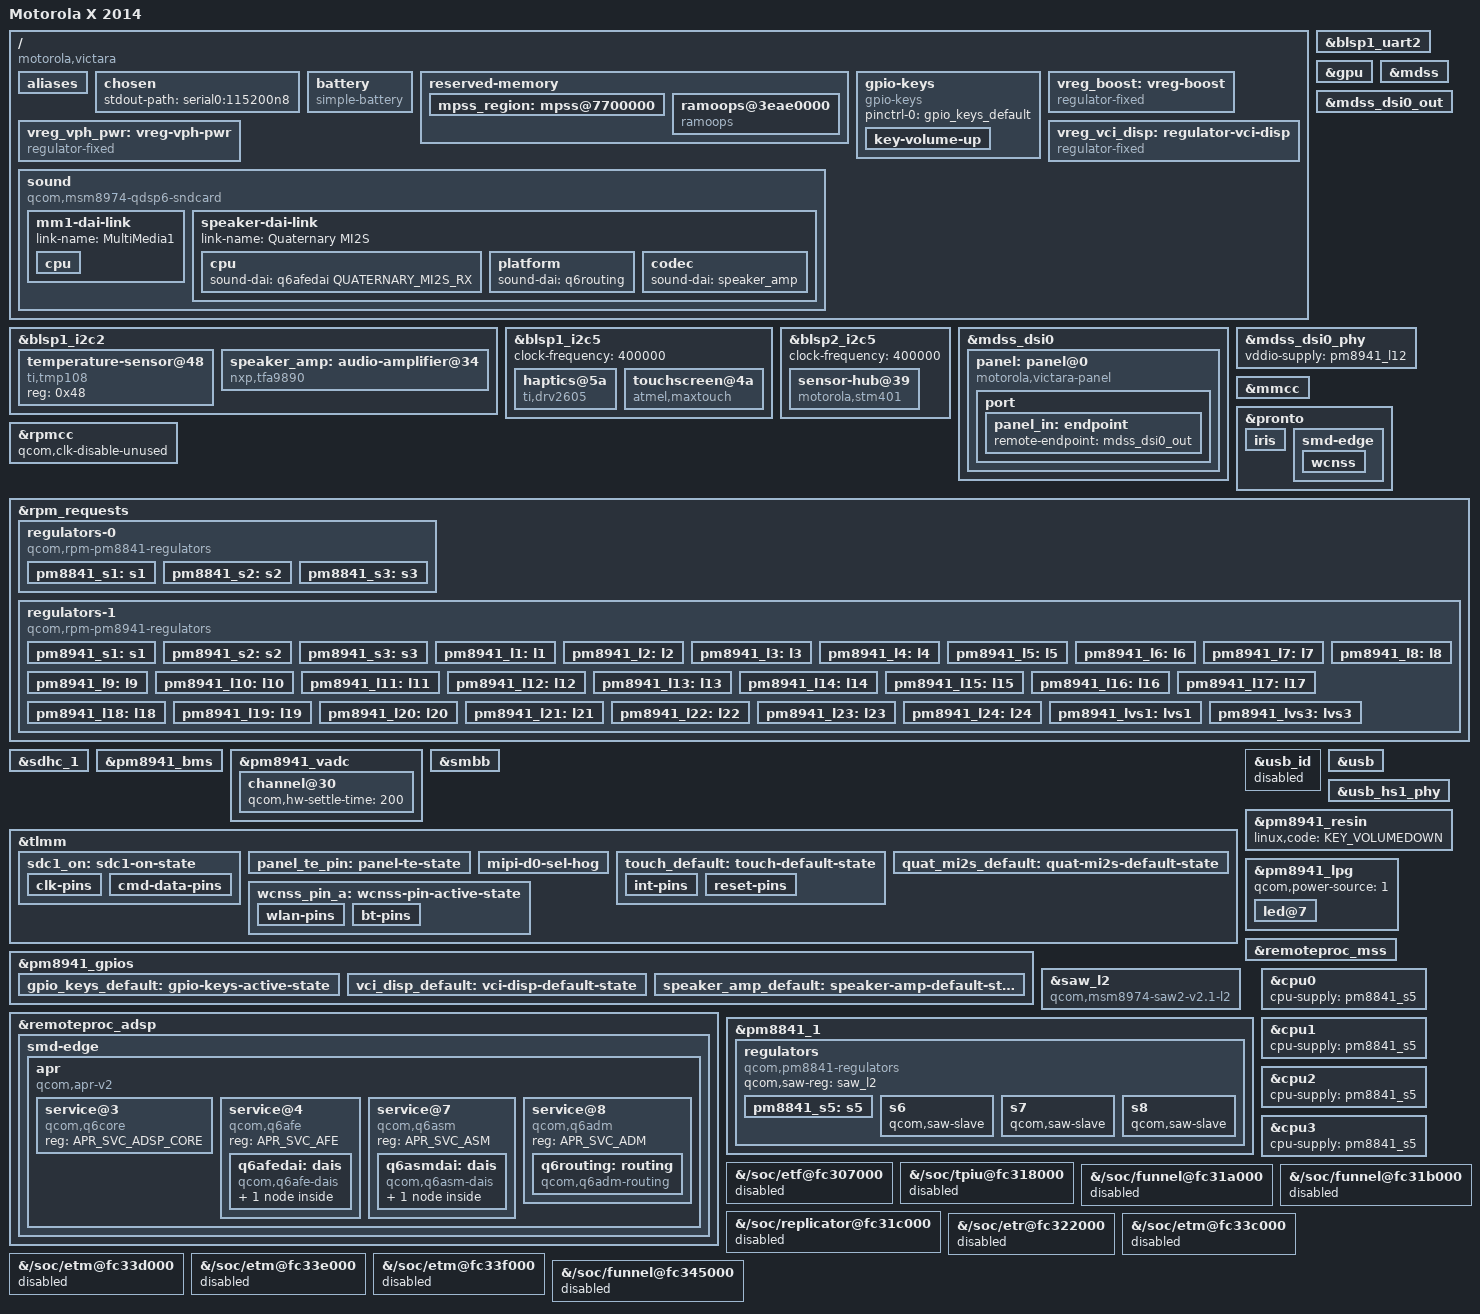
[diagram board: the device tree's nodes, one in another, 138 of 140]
// SPDX-License-Identifier: GPL-2.0
#include "qcom-msm8974pro.dtsi"
#include "pm8841.dtsi"
#include "pm8941.dtsi"
#include <dt-bindings/input/input.h>
#include <dt-bindings/input/ti-drv260x.h>
#include <dt-bindings/leds/common.h>
#include <dt-bindings/pinctrl/qcom,pmic-gpio.h>
#include <dt-bindings/soc/qcom,apr.h>
#include <dt-bindings/sound/qcom,q6afe.h>
#include <dt-bindings/sound/qcom,q6asm.h>

/delete-node/ &mpss_region;

/ {
       model = "Motorola X 2014";
       compatible = "motorola,victara", "qcom,msm8974pro", "qcom,msm8974";
       chassis-type = "handset";

       aliases {
               mmc0 = &sdhc_1;
               serial0 = &blsp1_uart2;
       };

       chosen {
               stdout-path = "serial0:115200n8";
       };

        battery: battery {
                compatible = "simple-battery";
                device-chemistry = "lithium-ion";
                charge-full-design-microamp-hours = <2281000>;
                voltage-min-design-microvolt = <3000000>;
                voltage-max-design-microvolt = <4200000>;
                factory-internal-resistance-micro-ohms = <188000>;

                ocv-capacity-celsius = <(-10) 0 23 60>;
                ocv-capacity-table-0 = <4300000 100>, <4266000 95>, <4209000 90>, <4156000 85>, <4106000 80>, <4058000 75>,
                                       <4002000 70>, <3954000 65>, <3910000 60>, <3873000 55>, <3843000 50>, <3820000 45>,
                                       <3802000 40>, <3791000 35>, <3782000 30>, <3767000 25>, <3742000 20>, <3714000 15>,
                                       <3696000 10>, <3693000 9>, <3689000 8>, <3683000 7>, <3669000 6>, <3640000 5>,
                                       <3594000 4>, <3529000 3>, <3438000 2>, <3293000 1>, <3000000 0>;
                ocv-capacity-table-1 = <4300000 100>, <4266000 95>, <4212000 90>, <4159000 85>, <4109000 80>, <4064000 75>,
                                       <4011000 70>, <3967000 65>, <3921000 60>, <3878000 55>, <3847000 50>, <3825000 45>,
                                       <3807000 40>, <3793000 35>, <3783000 30>, <3772000 25>, <3746000 20>, <3711000 15>,
                                       <3694000 10>, <3692000 9>, <3689000 8>, <3683000 7>, <3668000 6>, <3639000 5>,
                                       <3591000 4>, <3527000 3>, <3436000 2>, <3282000 1>, <3000000 0>;
                ocv-capacity-table-2 = <4300000 100>, <4262000 95>, <4207000 90>, <4155000 85>, <4105000 80>, <4059000 75>,
                                       <4011000 70>, <3970000 65>, <3933000 60>, <3877000 55>, <3847000 50>, <3825000 45>,
                                       <3807000 40>, <3793000 35>, <3780000 30>, <3763000 25>, <3736000 20>, <3695000 15>,
                                       <3685000 10>, <3683000 9>, <3681000 8>, <3675000 7>, <3656000 6>, <3624000 5>,
                                       <3577000 4>, <3512000 3>, <3422000 2>, <3280000 1>, <3000000 0>;
                ocv-capacity-table-3 = <4300000 100>, <4249000 95>, <4195000 90>, <4144000 85>, <4095000 80>, <4048000 75>,
                                       <4004000 70>, <3965000 65>, <3921000 60>, <3874000 55>, <3846000 50>, <3823000 45>,
                                       <3804000 40>, <3788000 35>, <3759000 30>, <3735000 25>, <3710000 20>, <3678000 15>,
                                       <3664000 10>, <3663000 9>, <3660000 8>, <3650000 7>, <3626000 6>, <3586000 5>,
                                       <3534000 4>, <3467000 3>, <3374000 2>, <3231000 1>, <3000000 0>;
        };

        reserved-memory {
                mpss_region: mpss@7700000 {
                        reg = <0x07700000 0x5a00000>;
                        no-map;
                };

                ramoops@3eae0000 {
                        compatible = "ramoops";
                        reg = <0x3eae0000 0x20000>;
                        console-size = <0x20000>;
                        record-size = <0x0>;
                        pmsg-size = <0x0>;
                        mem-type = <1>;
                };
        };

        gpio-keys {
                compatible = "gpio-keys";

                pinctrl-names = "default";
                pinctrl-0 = <&gpio_keys_default>;

                key-volume-up {
                        label = "volume_up";
                        gpios = <&pm8941_gpios 5 GPIO_ACTIVE_LOW>;
                        linux,code = <KEY_VOLUMEUP>;
                        wakeup-source;
                        debounce-interval = <15>;
                };
        };

       vreg_boost: vreg-boost {
                compatible = "regulator-fixed";

                regulator-name = "vreg-boost";
                regulator-min-microvolt = <3150000>;
                regulator-max-microvolt = <3150000>;

                regulator-always-on;
                regulator-boot-on;

                gpio = <&pm8941_gpios 21 GPIO_ACTIVE_HIGH>;
                enable-active-high;

                pinctrl-names = "default";
                pinctrl-0 = <&boost_bypass_n_pin>;
        };

        vreg_vph_pwr: vreg-vph-pwr {
                compatible = "regulator-fixed";
                regulator-name = "vph-pwr";

                regulator-min-microvolt = <3600000>;
                regulator-max-microvolt = <3600000>;

                regulator-always-on;
        };

        vreg_vci_disp: regulator-vci-disp {
                compatible = "regulator-fixed";
                regulator-name = "vci_disp";

                regulator-min-microvolt = <3300000>;
                regulator-max-microvolt = <3300000>;

                gpio = <&pm8941_gpios 14 GPIO_ACTIVE_HIGH>;
                enable-active-high;
                startup-delay-us = <300>;

                vin-supply = <&pm8941_l23>;

                regulator-boot-on;

                pinctrl-0 = <&vci_disp_default>;
                pinctrl-names = "default";
        };

        sound {
                compatible = "qcom,msm8974-qdsp6-sndcard";
                model = "msm8974";

                pinctrl-0 = <&quat_mi2s_default>;
                pinctrl-names = "default";

                mm1-dai-link {
                        link-name = "MultiMedia1";

                        cpu {
                                sound-dai = <&q6asmdai MSM_FRONTEND_DAI_MULTIMEDIA1>;
                        };
                };

                speaker-dai-link {
                        link-name = "Quaternary MI2S";

                        cpu {
                                sound-dai = <&q6afedai QUATERNARY_MI2S_RX>;
                        };

                        platform {
                                sound-dai = <&q6routing>;
                        };

                        codec {
                                sound-dai = <&speaker_amp>;
                        };
                };
        };
};

&blsp1_i2c2 {
        status = "okay";

        temperature-sensor@48 {
                compatible = "ti,tmp108";
                reg = <0x48>;
                #thermal-sensor-cells = <0>;
        };

        speaker_amp: audio-amplifier@34 {
                compatible = "nxp,tfa9890";
                reg = <0x34>;

                vddd-supply = <&pm8941_s3>;

                pinctrl-0 = <&speaker_amp_default>;
                pinctrl-names = "default";

                sound-name-prefix = "Speaker";
                #sound-dai-cells = <0>;
        };
};

&blsp1_i2c5 {
        status = "okay";
        clock-frequency = <400000>;

        haptics@5a {
                compatible = "ti,drv2605";
                reg = <0x5a>;

                vbat-supply = <&pm8941_5v>;
                enable-gpios = <&tlmm 45 GPIO_ACTIVE_HIGH>;

                mode = <DRV260X_ERM_MODE>;
                library-sel = <DRV260X_ERM_LIB_A>;
                vib-rated-mv = <2503>;
                vib-overdrive-mv = <3008>;
        };

        touchscreen@4a {
                compatible = "atmel,maxtouch";
                reg = <0x4a>;

                interrupts-extended = <&tlmm 62 IRQ_TYPE_EDGE_FALLING>;
                reset-gpios = <&tlmm 57 GPIO_ACTIVE_LOW>;

                vdda-supply = <&pm8941_l23>;
                vdd-supply = <&pm8941_s3>;

                pinctrl-0 = <&touch_default>;
                pinctrl-names = "default";
        };
};

&blsp1_uart2 {
       status = "okay";
};

&blsp2_i2c5 {
        status = "okay";
        clock-frequency = <400000>;

        sensor-hub@39 {
                compatible = "motorola,stm401";
                reg = <0x39>;

                interrupts-extended = <&tlmm 14 IRQ_TYPE_EDGE_RISING>,
                                      <&tlmm 95 IRQ_TYPE_EDGE_RISING>;
                interrupt-names = "data", "wakeup";

                reset-gpios = <&tlmm 145 GPIO_ACTIVE_LOW>;
                boot-gpios = <&tlmm 33 GPIO_ACTIVE_HIGH>;
                wakeup-gpios = <&tlmm 0 GPIO_ACTIVE_HIGH>;
                wakeup-ack-gpios = <&tlmm 1 GPIO_ACTIVE_HIGH>;

                vio-supply = <&pm8941_lvs1>;
                vdd-supply = <&pm8941_l17>;

                motorola,lux-table = <6 70 86 1174 2800 8000>;
                motorola,brightness-table = <12 20 25 55 80 111 165>;
                motorola,prox-settings = <0x6e 0x50 0x64 0x04>;
        };
};

&gpu {
        status = "okay";
};

&mdss {
        status = "okay";
};

&mdss_dsi0 {
        status = "okay";

        vdda-supply = <&pm8941_l2>;
        vddio-supply = <&pm8941_l12>;

        panel: panel@0 {
                compatible = "motorola,victara-panel";
                reg = <0>;

                vci-supply = <&vreg_vci_disp>;
                vddio-supply = <&pm8941_l12>;

                reset-gpios = <&pm8941_gpios 12 GPIO_ACTIVE_LOW>;

                pinctrl-0 = <&panel_te_pin>;
                pinctrl-names = "default";

                port {
                        panel_in: endpoint {
                                remote-endpoint = <&mdss_dsi0_out>;
                        };
                };
        };
};

&mdss_dsi0_out {
        remote-endpoint = <&panel_in>;
        data-lanes = <0 1 2 3>;
};

&mdss_dsi0_phy {
        status = "okay";

        vddio-supply = <&pm8941_l12>;
};

&mmcc {
        power-domains = <&rpmpd MSM8974_VDDGFX>;
        required-opps = <&rpmpd_opp_svs_soc>;
};

&pronto {
        status = "okay";

        vddmx-supply = <&pm8841_s1>;
        vddpx-supply = <&pm8941_s3>;

        pinctrl-names = "default";
        pinctrl-0 = <&wcnss_pin_a>;

        iris {
                vddxo-supply = <&pm8941_l6>;
                vddrfa-supply = <&pm8941_l11>;
                vddpa-supply = <&pm8941_l21>;
                vdddig-supply = <&pm8941_s3>;
        };

        smd-edge {
                qcom,remote-pid = <4>;
                label = "pronto";

                wcnss {
                        status = "okay";
                };
        };
};

&rpmcc {
        qcom,clk-disable-unused;
};

&rpm_requests {
        regulators-0 {
                compatible = "qcom,rpm-pm8841-regulators";

                pm8841_s1: s1 {
                        regulator-min-microvolt = <675000>;
                        regulator-max-microvolt = <1050000>;
                };

                pm8841_s2: s2 {
                        regulator-min-microvolt = <500000>;
                        regulator-max-microvolt = <1050000>;
                };

                pm8841_s3: s3 {
                        regulator-min-microvolt = <1050000>;
                        regulator-max-microvolt = <1050000>;
                };
        };

        regulators-1 {
                compatible = "qcom,rpm-pm8941-regulators";

                vdd_l1_l3-supply = <&pm8941_s1>;
                vdd_l2_lvs1_2_3-supply = <&pm8941_s3>;
                vdd_l4_l11-supply = <&pm8941_s1>;
                vdd_l5_l7-supply = <&pm8941_s2>;
                vdd_l6_l12_l14_l15-supply = <&pm8941_s2>;
                vdd_l8_l16_l18_l19-supply = <&vreg_vph_pwr>;
                vdd_l9_l10_l17_l22-supply = <&vreg_boost>;
                vdd_l13_l20_l23_l24-supply = <&vreg_boost>;
                vdd_l21-supply = <&vreg_boost>;

                pm8941_s1: s1 {
                        regulator-min-microvolt = <1300000>;
                        regulator-max-microvolt = <1300000>;

                        regulator-always-on;
                        regulator-boot-on;
                };

                pm8941_s2: s2 {
                        regulator-min-microvolt = <2150000>;
                        regulator-max-microvolt = <2150000>;

                        regulator-boot-on;
                };

                pm8941_s3: s3 {
                        regulator-min-microvolt = <1800000>;
                        regulator-max-microvolt = <1800000>;
                        regulator-system-load = <154000>;

                        regulator-always-on;
                        regulator-boot-on;
                        regulator-allow-set-load;
                };

                pm8941_l1: l1 {
                        regulator-min-microvolt = <1225000>;
                        regulator-max-microvolt = <1225000>;

                        regulator-always-on;
                        regulator-boot-on;
                };

                pm8941_l2: l2 {
                        regulator-min-microvolt = <1200000>;
                        regulator-max-microvolt = <1200000>;
                };

                pm8941_l3: l3 {
                        regulator-min-microvolt = <1225000>;
                        regulator-max-microvolt = <1225000>;
                };

                pm8941_l4: l4 {
                        regulator-min-microvolt = <1225000>;
                        regulator-max-microvolt = <1225000>;
                };

                pm8941_l5: l5 {
                        regulator-min-microvolt = <1800000>;
                        regulator-max-microvolt = <1800000>;
                };

                pm8941_l6: l6 {
                        regulator-min-microvolt = <1800000>;
                        regulator-max-microvolt = <1800000>;

                        regulator-boot-on;
                };

                pm8941_l7: l7 {
                        regulator-min-microvolt = <1800000>;
                        regulator-max-microvolt = <1800000>;

                        regulator-boot-on;
                };

                pm8941_l8: l8 {
                        regulator-min-microvolt = <1800000>;
                        regulator-max-microvolt = <1800000>;
                };

                pm8941_l9: l9 {
                        regulator-min-microvolt = <1800000>;
                        regulator-max-microvolt = <2950000>;
                };

                pm8941_l10: l10 {
                        regulator-min-microvolt = <1800000>;
                        regulator-max-microvolt = <2950000>;
                };

                pm8941_l11: l11 {
                        regulator-min-microvolt = <1225000>;
                        regulator-max-microvolt = <1350000>;
                };

                pm8941_l12: l12 {
                        regulator-min-microvolt = <1800000>;
                        regulator-max-microvolt = <1800000>;

                        regulator-always-on;
                        regulator-boot-on;
                        regulator-allow-set-load;
                };

                pm8941_l13: l13 {
                        regulator-min-microvolt = <1800000>;
                        regulator-max-microvolt = <2950000>;

                        regulator-boot-on;
                };

                pm8941_l14: l14 {
                        regulator-min-microvolt = <1800000>;
                        regulator-max-microvolt = <1800000>;
                };

                pm8941_l15: l15 {
                        regulator-min-microvolt = <2050000>;
                        regulator-max-microvolt = <2050000>;
                };

                pm8941_l16: l16 {
                        regulator-min-microvolt = <2700000>;
                        regulator-max-microvolt = <2700000>;
                };

                pm8941_l17: l17 {
                        regulator-min-microvolt = <2850000>;
                        regulator-max-microvolt = <2850000>;
                };

                pm8941_l18: l18 {
                        regulator-min-microvolt = <2850000>;
                        regulator-max-microvolt = <2850000>;
                };

                pm8941_l19: l19 {
                        regulator-min-microvolt = <2900000>;
                        regulator-max-microvolt = <3350000>;
                };

                pm8941_l20: l20 {
                        regulator-min-microvolt = <2950000>;
                        regulator-max-microvolt = <2950000>;

                        regulator-system-load = <200000>;
                        regulator-allow-set-load;
                        regulator-boot-on;
                };

                pm8941_l21: l21 {
                        regulator-min-microvolt = <2900000>;
                        regulator-max-microvolt = <3350000>;

                        regulator-boot-on;
                        regulator-always-on;
                };

                pm8941_l22: l22 {
                        regulator-min-microvolt = <3000000>;
                        regulator-max-microvolt = <3000000>;
                        regulator-allow-set-load;
                };

                pm8941_l23: l23 {
                        regulator-min-microvolt = <3300000>;
                        regulator-max-microvolt = <3300000>;
                };

                pm8941_l24: l24 {
                        regulator-min-microvolt = <3075000>;
                        regulator-max-microvolt = <3075000>;

                        regulator-boot-on;
                };

                pm8941_lvs1: lvs1 {};

                pm8941_lvs3: lvs3 {};
        };
};

&sdhc_1 {
        status = "okay";
                        
        vmmc-supply = <&pm8941_l20>;
        vqmmc-supply = <&pm8941_s3>;

        pinctrl-names = "default", "sleep";
        pinctrl-0 = <&sdc1_on>;
        pinctrl-1 = <&sdc1_off>;
};

&pm8941_bms {
        io-channels = <&pm8941_vadc VADC_VBAT_SNS>,
                      <&pm8941_vadc VADC_REF_625MV>,
                      <&pm8941_vadc VADC_REF_1250MV>,
                      <&pm8941_vadc VADC_LR_MUX1_BAT_THERM>,
                      <&pm8941_vadc VADC_GND_REF>,
                      <&pm8941_vadc VADC_VDD_VADC>;
        io-channel-names = "vbat", "ref-625mv", "ref-1250mv", "therm", "gnd-ref", "vdd-vadc";

        qcom,fcc-temp-celsius = <(-10) 0 23 60>;
        qcom,fcc-microamp-hours = <1919000 2155000 2281000 2236000>;

        qcom,shutdown-soc-valid-limit-percent = <100>;

        qcom,rbatt-sf-celsius = <(-10) 0 23 60>;
        qcom,rbatt-sf-capacity = <100 95 90 85 80 75 70 65 60 55 50 45 40 35 30 25 20 15 10 9 8 7 6 5 4 3 2 1 0>;
        qcom,rbatt-sf = <607 314 100 62>, <615 323 104 64>, <624 332 107 67>, <636 342 111 71>,
                        <650 352 116 74>, <667 376 125 78>, <667 386 133 79>, <665 395 150 85>,
                        <656 378 163 89>, <655 359 119 73>, <670 360 113 73>, <698 375 121 76>,
                        <735 394 128 80>, <800 423 136 87>, <902 476 144 77>, <1015 553 138 74>,
                        <1108 620 135 76>, <1204 681 137 76>, <1200 685 148 80>, <1239 693 145 81>,
                        <1281 721 151 81>, <1327 745 156 83>, <1368 765 156 84>, <1402 780 160 81>,
                        <1451 805 165 81>, <1524 849 169 81>, <1624 907 178 87>, <1819 1018 201 201>,
                        <3032 1951 615 615>;

        monitored-battery = <&battery>;

        status = "okay";
};

&pm8941_vadc {
        channel@30 {
                qcom,hw-settle-time = <200>;
        };
};

&smbb {
        qcom,fast-charge-safe-current = <3000000>;
        qcom,fast-charge-current-limit = <2600000>;
        qcom,fast-charge-safe-voltage = <4400000>;
        qcom,fast-charge-high-threshold-voltage = <4200000>;
        qcom,auto-recharge-threshold-voltage = <4050000>;
        qcom,minimum-input-voltage = <4300000>;

        status = "okay";
};

&tlmm {         
        sdc1_on: sdc1-on-state {
                clk-pins { 
                        pins = "sdc1_clk";
                        drive-strength = <16>;
                        bias-disable;
                };

                cmd-data-pins {
                        pins = "sdc1_cmd", "sdc1_data";
                        drive-strength = <10>;
                        bias-pull-up;
                };
        };

        panel_te_pin: panel-te-state {
                pins = "gpio12";
                function = "mdp_vsync";
                drive-strength = <2>;
                bias-disable;
        };

        mipi-d0-sel-hog {
                gpio-hog;
                gpios = <129 GPIO_ACTIVE_HIGH>;
                output-low;
                line-name = "mipi-d0-sel";
        };

        touch_default: touch-default-state {
                int-pins {
                        pins = "gpio62";
                        function = "gpio";
                        drive-strength = <2>;
                        bias-disable;
                };

                reset-pins {
                        pins = "gpio57";
                        function = "gpio";
                        drive-strength = <2>;
                        bias-disable;
                };
        };

        quat_mi2s_default: quat-mi2s-default-state {
                pins = "gpio58", "gpio59", "gpio60", "gpio61";
                function = "qua_mi2s";
                drive-strength = <8>;
                bias-disable;
        };

        wcnss_pin_a: wcnss-pin-active-state {
                wlan-pins {
                        pins = "gpio36", "gpio37", "gpio38", "gpio39", "gpio40";
                        function = "wlan";

                        drive-strength = <6>;
                        bias-pull-down;
                };

                bt-pins {
                        pins = "gpio35", "gpio43", "gpio44";
                        function = "bt";

                        drive-strength = <2>;
                        bias-pull-down;
                };
        };
};

&usb_id {
        status = "disabled";
};

&usb {          
        phys = <&usb_hs1_phy>;
        phy-select = <&tcsr 0xb000 0>;
        extcon = <&smbb>;
        vbus-supply = <&chg_otg>;

        hnp-disable;
        srp-disable;
        adp-disable;    
                        
        status = "okay";
};              

&usb_hs1_phy {  
        status = "okay";
                        
        v1p8-supply = <&pm8941_l6>;
        v3p3-supply = <&pm8941_l24>;
        
        extcon = <&smbb>;
        qcom,init-seq = /bits/ 8 <0x1 0x64>;
};

&pm8941_gpios {
        gpio_keys_default: gpio-keys-active-state {
                pins = "gpio5";
                function = "normal";

                bias-pull-up;
                power-source = <PM8941_GPIO_S3>;
        };

        vci_disp_default: vci-disp-default-state {
                pins = "gpio14";
                function = "normal";

                bias-disable;
                drive-push-pull;
                power-source = <PM8941_GPIO_S3>;
                qcom,drive-strength = <PMIC_GPIO_STRENGTH_LOW>;
        };

        speaker_amp_default: speaker-amp-default-state {
                pins = "gpio20";
                function = "normal";

                output-low;
                power-source = <PM8941_GPIO_S3>;
        };
};

&pm8941_resin {
        linux,code = <KEY_VOLUMEDOWN>;
        status = "okay";
};

&pm8941_lpg {
        status = "okay";

        qcom,power-source = <1>;

        led@7 {
                reg = <7>;
                color = <LED_COLOR_ID_GREEN>;
                function = LED_FUNCTION_CHARGING;
        };
};

&remoteproc_adsp {
        status = "okay";

        smd-edge {
                apr {
                        compatible = "qcom,apr-v2";
                        qcom,smd-channels = "apr_audio_svc";
                        qcom,domain = <APR_DOMAIN_ADSP>;
                        #address-cells = <1>;
                        #size-cells = <0>;

                        service@3 {
                                compatible = "qcom,q6core";
                                reg = <APR_SVC_ADSP_CORE>;
                        };

                        service@4 {
                                compatible = "qcom,q6afe";
                                reg = <APR_SVC_AFE>;

                                q6afedai: dais {
                                        compatible = "qcom,q6afe-dais";
                                        #address-cells = <1>;
                                        #size-cells = <0>;
                                        #sound-dai-cells = <1>;

                                        dai@22 {
                                                reg = <QUATERNARY_MI2S_RX>;
                                                qcom,sd-lines = <1>;
                                        };
                                };
                        };

                        service@7 {
                                compatible = "qcom,q6asm";
                                reg = <APR_SVC_ASM>;

                                q6asmdai: dais {
                                        compatible = "qcom,q6asm-dais";
                                        #address-cells = <1>;
                                        #size-cells = <0>;
                                        #sound-dai-cells = <1>;

                                        dai@0 {
                                                reg = <MSM_FRONTEND_DAI_MULTIMEDIA1>;
                                                direction = <Q6ASM_DAI_RX>;
                                        };
                                };
                        };

                        service@8 {
                                compatible = "qcom,q6adm";
                                reg = <APR_SVC_ADM>;

                                q6routing: routing {
                                        compatible = "qcom,q6adm-routing";
                                        #sound-dai-cells = <0>;
                                };
                        };
                };
        };
};

&remoteproc_mss {
        status = "okay";

        mss-supply = <&pm8841_s3>;
        mx-supply = <&pm8841_s1>;
        pll-supply = <&pm8941_l12>;
};

&saw_l2 {
        compatible = "qcom,msm8974-saw2-v2.1-l2", "qcom,saw2", "syscon";
};

&pm8841_1 {
        regulators {
                compatible = "qcom,pm8841-regulators";
                qcom,saw-reg = <&saw_l2>;

                pm8841_s5: s5 {
                        qcom,saw-leader;
                        regulator-name = "vdd_apc";
                        regulator-min-microvolt = <800000>;
                        regulator-max-microvolt = <1080000>;
                        regulator-always-on;
                };

                s6 {
                        qcom,saw-slave;
                };

                s7 {
                        qcom,saw-slave;
                };

                s8 {
                        qcom,saw-slave;
                };
        };
};

&cpu0 {
        cpu-supply = <&pm8841_s5>;
};

&cpu1 {
        cpu-supply = <&pm8841_s5>;
};

&cpu2 {
        cpu-supply = <&pm8841_s5>;
};

&cpu3 {
        cpu-supply = <&pm8841_s5>;
};

&{/soc/etf@fc307000} {
        status = "disabled";
};

&{/soc/tpiu@fc318000} {
        status = "disabled";
};

&{/soc/funnel@fc31a000} {
        status = "disabled";
};

&{/soc/funnel@fc31b000} {
        status = "disabled";
};

&{/soc/replicator@fc31c000} {
        status = "disabled";
};

&{/soc/etr@fc322000} {
        status = "disabled";
};

&{/soc/etm@fc33c000} {
        status = "disabled";
};

&{/soc/etm@fc33d000} {
        status = "disabled";
};

&{/soc/etm@fc33e000} {
        status = "disabled";
};

&{/soc/etm@fc33f000} {
        status = "disabled";
};

&{/soc/funnel@fc345000} {
        status = "disabled";
};
